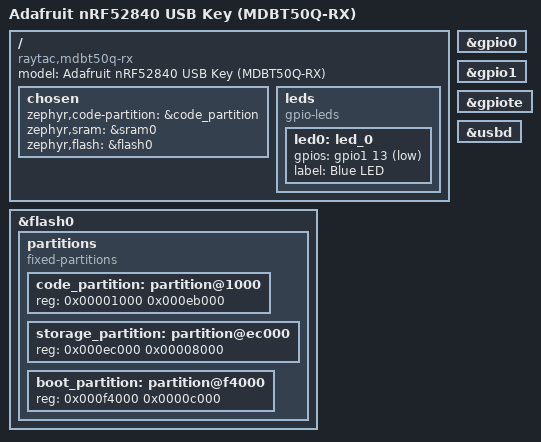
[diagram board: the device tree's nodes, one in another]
/dts-v1/;
#include <nordic/nrf52840_qiaa.dtsi>

/ {
    model = "Adafruit nRF52840 USB Key (MDBT50Q-RX)";
    compatible = "raytac,mdbt50q-rx";

    chosen {
        zephyr,code-partition = &code_partition;
        zephyr,sram = &sram0;
        zephyr,flash = &flash0;
    };

    leds {
        compatible = "gpio-leds";
        led0: led_0 {
            gpios = <&gpio1 13 GPIO_ACTIVE_LOW>;
            label = "Blue LED";
        };
    };
};

&gpio0 {
    status = "okay";
};

&gpio1 {
    status = "okay";
};

&gpiote {
    status = "okay";
};

zephyr_udc0: &usbd {
    status = "okay";
};

&flash0 {
    partitions {
        compatible = "fixed-partitions";
        #address-cells = <1>;
        #size-cells = <1>;

        /* MBR occupies 0x0–0x1000 (4 KB) */
        /* No SoftDevice installed — app starts right after MBR */

        /* Application */
        code_partition: partition@1000 {
            reg = <0x00001000 0x000eb000>;
        };

        /* Non-volatile storage for settings/pairing */
        storage_partition: partition@ec000 {
            reg = <0x000ec000 0x00008000>;
        };

        /* UF2 bootloader */
        boot_partition: partition@f4000 {
            reg = <0x000f4000 0x0000c000>;
        };
    };
};
